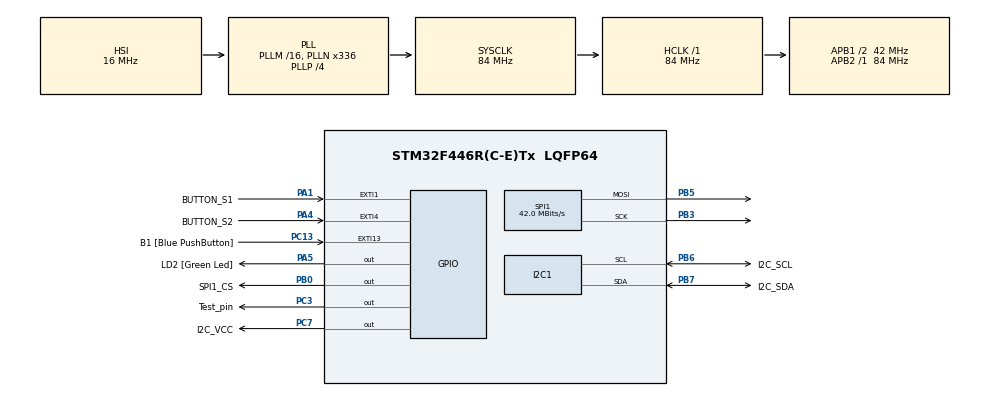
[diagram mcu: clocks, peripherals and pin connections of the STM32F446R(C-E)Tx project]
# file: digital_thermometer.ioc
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Mcu.Family=STM32F4
Mcu.Name=STM32F446R(C-E)Tx
Mcu.Package=LQFP64
NVIC.EXTI1_IRQn=true\:2\:0\:true\:false\:true\:true\:true\:true
NVIC.EXTI4_IRQn=true\:2\:0\:true\:false\:true\:true\:true\:true
NVIC.PriorityGroup=NVIC_PRIORITYGROUP_2
NVIC.SPI1_IRQn=true\:1\:0\:true\:false\:true\:true\:true\:true
NVIC.TIM6_DAC_IRQn=true\:0\:0\:false\:false\:true\:true\:true\:true
PA1.GPIO_Label=BUTTON_S1
PA1.GPIO_ModeDefaultEXTI=GPIO_MODE_IT_RISING_FALLING
PA1.GPIO_PuPd=GPIO_PULLUP
PA1.Signal=GPXTI1
PA13.GPIO_Label=TMS
PA13.Mode=Serial_Wire
PA13.Signal=SYS_JTMS-SWDIO
PA14.GPIO_Label=TCK
PA14.Mode=Serial_Wire
PA14.Signal=SYS_JTCK-SWCLK
PA2.GPIO_Label=USART_TX
PA2.Signal=USART2_TX
PA3.GPIO_Label=USART_RX
PA3.Signal=USART2_RX
PA4.GPIO_Label=BUTTON_S2
PA4.GPIO_ModeDefaultEXTI=GPIO_MODE_IT_RISING_FALLING
PA4.GPIO_PuPd=GPIO_PULLUP
PA4.Signal=GPXTI4
PA5.GPIO_Label=LD2 [Green Led]
PA5.Signal=GPIO_Output
PB0.GPIO_Label=SPI1_CS
PB0.Signal=GPIO_Output
PB3.Mode=TX_Only_Simplex_Unidirect_Master
PB3.Signal=SPI1_SCK
PB5.Mode=TX_Only_Simplex_Unidirect_Master
PB5.Signal=SPI1_MOSI
PB6.GPIO_Label=I2C_SCL
PB6.Mode=I2C
PB6.Signal=I2C1_SCL
PB7.GPIO_Label=I2C_SDA
PB7.Mode=I2C
PB7.Signal=I2C1_SDA
PC13.GPIO_Label=B1 [Blue PushButton]
PC13.GPIO_ModeDefaultEXTI=GPIO_MODE_IT_FALLING
PC13.Signal=GPXTI13
PC14-OSC32_IN.Mode=LSE-External-Oscillator
PC14-OSC32_IN.Signal=RCC_OSC32_IN
PC15-OSC32_OUT.Mode=LSE-External-Oscillator
PC15-OSC32_OUT.Signal=RCC_OSC32_OUT
PC3.GPIO_Label=Test_pin
PC3.Signal=GPIO_Output
PC7.GPIO_Label=I2C_VCC
PC7.Signal=GPIO_Output
ProjectManager.HeapSize=0x200
ProjectManager.StackSize=0x400
ProjectManager.TargetToolchain=STM32CubeIDE
RCC.48MHZClocksFreq_Value=84000000
RCC.AHBFreq_Value=84000000
RCC.APB1CLKDivider=RCC_HCLK_DIV2
RCC.APB1Freq_Value=42000000
RCC.APB1TimFreq_Value=84000000
RCC.APB2Freq_Value=84000000
RCC.APB2TimFreq_Value=84000000
RCC.CortexFreq_Value=84000000
RCC.FLatency-AdvancedSettings=FLASH_LATENCY_2
RCC.HCLKFreq_Value=84000000
RCC.HSE_VALUE=8000000
RCC.HSI_VALUE=16000000
RCC.PLLN=336
RCC.PLLP=RCC_PLLP_DIV4
RCC.SYSCLKFreq_VALUE=84000000
RCC.SYSCLKSource=RCC_SYSCLKSOURCE_PLLCLK
RCC.USBFreq_Value=168000000
RCC.VCOOutputFreq_Value=336000000
SPI1.CalculateBaudRate=42.0 MBits/s
SPI1.DataSize=SPI_DATASIZE_16BIT
SPI1.Direction=SPI_DIRECTION_2LINES
SPI1.Mode=SPI_MODE_MASTER
SPI1.VirtualType=VM_MASTER
TIM6.AutoReloadPreload=TIM_AUTORELOAD_PRELOAD_DISABLE
TIM6.Period=1
TIM6.Prescaler=150
VP_TIM6_VS_ClockSourceINT.Mode=Enable_Timer
board=NUCLEO-F446RE

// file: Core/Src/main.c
/* USER CODE BEGIN Header */

/*
 * digital_thermomether
 * digital thermometer built using stm32f446ret, AHT20 sensor and multi-function shield
 * Copyright (C) 2025 Andrew Kushyk
 *
 * This program is free software: you can redistribute it and/or modify
 * it under the terms of the GNU Affero General Public License as published
 * by the Free Software Foundation, either version 3 of the License, or
 * (at your option) any later version.
 *
 * This program is distributed in the hope that it will be useful,
 * but WITHOUT ANY WARRANTY; without even the implied warranty of
 * MERCHANTABILITY or FITNESS FOR A PARTICULAR PURPOSE.  See the
 * GNU Affero General Public License for more details.
 *
 * You should have received a copy of the GNU Affero General Public License
 * along with this program.  If not, see <https://www.gnu.org/licenses/>.
 */

/* USER CODE END Header */
#include "main.h"

/* USER CODE BEGIN Includes */
#include "character_generator.h"
#include "business_logic.h"
#include "button_hmi_api.h"
#include <stdio.h>
#include <string.h>
/* USER CODE END Includes */

I2C_HandleTypeDef hi2c1;

SPI_HandleTypeDef hspi1;

TIM_HandleTypeDef htim6;

void SystemClock_Config(void);
static void MX_GPIO_Init(void);
static void MX_SPI1_Init(void);
static void MX_TIM6_Init(void);
static void MX_I2C1_Init(void);

int main(void)
{

  /* MCU Configuration--------------------------------------------------------*/

  /* Reset of all peripherals, Initializes the Flash interface and the Systick. */
  HAL_Init();

  /* Configure the system clock */
  SystemClock_Config();

  /* Initialize all configured peripherals */
  MX_GPIO_Init();
  MX_SPI1_Init();
  MX_TIM6_Init();
  MX_I2C1_Init();
  /* USER CODE BEGIN 2 */
	if(BL_STATUS_OK != bl_run_sensor(&hi2c1)) {
		return 1;
	}
	bl_init_buttons();
	api_char_gen.init(&hspi1, &htim6, SPI1_CS_GPIO_Port, SPI1_CS_Pin);
  /* USER CODE END 2 */

  /* Infinite loop */
  /* USER CODE BEGIN WHILE */
	while (1)
	{
		if (BL_STATUS_OK != bl_process_sensor_data(&hi2c1)) {
			return 2;
		}

		bl_spi_transmit_sensor_data();
		HAL_Delay(100);
    /* USER CODE END WHILE */

	}
}

void SystemClock_Config(void)
{
  RCC_OscInitTypeDef RCC_OscInitStruct = {0};
  RCC_ClkInitTypeDef RCC_ClkInitStruct = {0};

  /** Configure the main internal regulator output voltage
  */
  __HAL_RCC_PWR_CLK_ENABLE();
  __HAL_PWR_VOLTAGESCALING_CONFIG(PWR_REGULATOR_VOLTAGE_SCALE3);

  /** Initializes the RCC Oscillators according to the specified parameters
  * in the RCC_OscInitTypeDef structure.
  */
  RCC_OscInitStruct.OscillatorType = RCC_OSCILLATORTYPE_HSI;
  RCC_OscInitStruct.HSIState = RCC_HSI_ON;
  RCC_OscInitStruct.HSICalibrationValue = RCC_HSICALIBRATION_DEFAULT;
  RCC_OscInitStruct.PLL.PLLState = RCC_PLL_ON;
  RCC_OscInitStruct.PLL.PLLSource = RCC_PLLSOURCE_HSI;
  RCC_OscInitStruct.PLL.PLLM = 16;
  RCC_OscInitStruct.PLL.PLLN = 336;
  RCC_OscInitStruct.PLL.PLLP = RCC_PLLP_DIV4;
  RCC_OscInitStruct.PLL.PLLQ = 2;
  RCC_OscInitStruct.PLL.PLLR = 2;
  if (HAL_RCC_OscConfig(&RCC_OscInitStruct) != HAL_OK)
  {
    Error_Handler();
  }

  /** Initializes the CPU, AHB and APB buses clocks
  */
  RCC_ClkInitStruct.ClockType = RCC_CLOCKTYPE_HCLK|RCC_CLOCKTYPE_SYSCLK
                              |RCC_CLOCKTYPE_PCLK1|RCC_CLOCKTYPE_PCLK2;
  RCC_ClkInitStruct.SYSCLKSource = RCC_SYSCLKSOURCE_PLLCLK;
  RCC_ClkInitStruct.AHBCLKDivider = RCC_SYSCLK_DIV1;
  RCC_ClkInitStruct.APB1CLKDivider = RCC_HCLK_DIV2;
  RCC_ClkInitStruct.APB2CLKDivider = RCC_HCLK_DIV1;

  if (HAL_RCC_ClockConfig(&RCC_ClkInitStruct, FLASH_LATENCY_2) != HAL_OK)
  {
    Error_Handler();
  }
}

static void MX_I2C1_Init(void)
{

  hi2c1.Instance = I2C1;
  hi2c1.Init.ClockSpeed = 100000;
  hi2c1.Init.DutyCycle = I2C_DUTYCYCLE_2;
  hi2c1.Init.OwnAddress1 = 0;
  hi2c1.Init.AddressingMode = I2C_ADDRESSINGMODE_7BIT;
  hi2c1.Init.DualAddressMode = I2C_DUALADDRESS_DISABLE;
  hi2c1.Init.OwnAddress2 = 0;
  hi2c1.Init.GeneralCallMode = I2C_GENERALCALL_DISABLE;
  hi2c1.Init.NoStretchMode = I2C_NOSTRETCH_DISABLE;
  if (HAL_I2C_Init(&hi2c1) != HAL_OK)
  {
    Error_Handler();
  }

}

static void MX_SPI1_Init(void)
{

  /* SPI1 parameter configuration*/
  hspi1.Instance = SPI1;
  hspi1.Init.Mode = SPI_MODE_MASTER;
  hspi1.Init.Direction = SPI_DIRECTION_2LINES;
  hspi1.Init.DataSize = SPI_DATASIZE_16BIT;
  hspi1.Init.CLKPolarity = SPI_POLARITY_LOW;
  hspi1.Init.CLKPhase = SPI_PHASE_1EDGE;
  hspi1.Init.NSS = SPI_NSS_SOFT;
  hspi1.Init.BaudRatePrescaler = SPI_BAUDRATEPRESCALER_2;
  hspi1.Init.FirstBit = SPI_FIRSTBIT_MSB;
  hspi1.Init.TIMode = SPI_TIMODE_DISABLE;
  hspi1.Init.CRCCalculation = SPI_CRCCALCULATION_DISABLE;
  hspi1.Init.CRCPolynomial = 10;
  if (HAL_SPI_Init(&hspi1) != HAL_OK)
  {
    Error_Handler();
  }

}

static void MX_TIM6_Init(void)
{

  TIM_MasterConfigTypeDef sMasterConfig = {0};

  htim6.Instance = TIM6;
  htim6.Init.Prescaler = 150;
  htim6.Init.CounterMode = TIM_COUNTERMODE_UP;
  htim6.Init.Period = 1;
  htim6.Init.AutoReloadPreload = TIM_AUTORELOAD_PRELOAD_DISABLE;
  if (HAL_TIM_Base_Init(&htim6) != HAL_OK)
  {
    Error_Handler();
  }
  sMasterConfig.MasterOutputTrigger = TIM_TRGO_RESET;
  sMasterConfig.MasterSlaveMode = TIM_MASTERSLAVEMODE_DISABLE;
  if (HAL_TIMEx_MasterConfigSynchronization(&htim6, &sMasterConfig) != HAL_OK)
  {
    Error_Handler();
  }

}

static void MX_GPIO_Init(void)
{
  GPIO_InitTypeDef GPIO_InitStruct = {0};

  /* GPIO Ports Clock Enable */
  __HAL_RCC_GPIOC_CLK_ENABLE();
  __HAL_RCC_GPIOA_CLK_ENABLE();
  __HAL_RCC_GPIOB_CLK_ENABLE();

  /*Configure GPIO pin Output Level */
  HAL_GPIO_WritePin(GPIOC, Test_pin_Pin|I2C_VCC_Pin, GPIO_PIN_RESET);

  /*Configure GPIO pin Output Level */
  HAL_GPIO_WritePin(LD2_GPIO_Port, LD2_Pin, GPIO_PIN_RESET);

  /*Configure GPIO pin Output Level */
  HAL_GPIO_WritePin(SPI1_CS_GPIO_Port, SPI1_CS_Pin, GPIO_PIN_RESET);

  /*Configure GPIO pin : B1_Pin */
  GPIO_InitStruct.Pin = B1_Pin;
  GPIO_InitStruct.Mode = GPIO_MODE_IT_FALLING;
  GPIO_InitStruct.Pull = GPIO_NOPULL;
  HAL_GPIO_Init(B1_GPIO_Port, &GPIO_InitStruct);

  /*Configure GPIO pins : Test_pin_Pin I2C_VCC_Pin */
  GPIO_InitStruct.Pin = Test_pin_Pin|I2C_VCC_Pin;
  GPIO_InitStruct.Mode = GPIO_MODE_OUTPUT_PP;
  GPIO_InitStruct.Pull = GPIO_NOPULL;
  GPIO_InitStruct.Speed = GPIO_SPEED_FREQ_LOW;
  HAL_GPIO_Init(GPIOC, &GPIO_InitStruct);

  /*Configure GPIO pins : BUTTON_S1_Pin BUTTON_S2_Pin */
  GPIO_InitStruct.Pin = BUTTON_S1_Pin|BUTTON_S2_Pin;
  GPIO_InitStruct.Mode = GPIO_MODE_IT_RISING_FALLING;
  GPIO_InitStruct.Pull = GPIO_PULLUP;
  HAL_GPIO_Init(GPIOA, &GPIO_InitStruct);

  /*Configure GPIO pins : USART_TX_Pin USART_RX_Pin */
  GPIO_InitStruct.Pin = USART_TX_Pin|USART_RX_Pin;
  GPIO_InitStruct.Mode = GPIO_MODE_AF_PP;
  GPIO_InitStruct.Pull = GPIO_NOPULL;
  GPIO_InitStruct.Speed = GPIO_SPEED_FREQ_VERY_HIGH;
  GPIO_InitStruct.Alternate = GPIO_AF7_USART2;
  HAL_GPIO_Init(GPIOA, &GPIO_InitStruct);

  /*Configure GPIO pin : LD2_Pin */
  GPIO_InitStruct.Pin = LD2_Pin;
  GPIO_InitStruct.Mode = GPIO_MODE_OUTPUT_PP;
  GPIO_InitStruct.Pull = GPIO_NOPULL;
  GPIO_InitStruct.Speed = GPIO_SPEED_FREQ_LOW;
  HAL_GPIO_Init(LD2_GPIO_Port, &GPIO_InitStruct);

  /*Configure GPIO pin : SPI1_CS_Pin */
  GPIO_InitStruct.Pin = SPI1_CS_Pin;
  GPIO_InitStruct.Mode = GPIO_MODE_OUTPUT_PP;
  GPIO_InitStruct.Pull = GPIO_NOPULL;
  GPIO_InitStruct.Speed = GPIO_SPEED_FREQ_LOW;
  HAL_GPIO_Init(SPI1_CS_GPIO_Port, &GPIO_InitStruct);

  /* EXTI interrupt init*/
  HAL_NVIC_SetPriority(EXTI1_IRQn, 2, 0);
  HAL_NVIC_EnableIRQ(EXTI1_IRQn);

  HAL_NVIC_SetPriority(EXTI4_IRQn, 2, 0);
  HAL_NVIC_EnableIRQ(EXTI4_IRQn);

}

void Error_Handler(void)
{
	__disable_irq();
	while (1)
	{
	}
}
